# CY8C5568AXI_060 register map
File version: 0.1
CY8C55
Registers are 8-bit, read-write, no defined reset value unless marked. A register's access mark holds for its fields unless they carry their own. Offsets are from the block's base; lines under a group give offsets from that group; [hi:lo] are bit positions; {n}, {i} and the like mark numbered series; 'fields as' and 'values as' point back to an identical list; <NAME> marks a mode.

## Memory map
0x40004614 ADC_Sharp_1 size 0x158D — SAR ADC
0x40004616 ADC_Sharp_2 size 0x158D — SAR ADC
0x40006424 UART_Asser size 0x40 — UART
0x40006425 UART_XBee size 0x47 — UART
0x40006524 PWM_LanceurGauche size 0x72
0x40006526 PWM_LanceurDroit size 0x72
0x40006528 PWM_Queue size 0x72

## ADC_Sharp_1 — SAR ADC
Base 0x40004614
0x00 SAR_TR0 — SAR trim register
{0x12EC+i} SAR_CSR{i} (i=0..6) — SAR status and control register {i}
0x150C SAR_SW0 — SAR Analog Routing Register 0
{0x150C+i} SAR_SW{i} (i=2..4) — SAR Analog Routing Register {i}
0x1512 SAR_SW6 — SAR Analog Routing Register 6
0x1513 SAR_CLK — SAR Clock Selection Register
0x158C SAR_WRK 16-bit — SAR working register

## UART_Asser — UART
Base 0x40006424
0x00 RX_UART_Asser_RX_ADDRESS1 — RX Address1 Register
0x10 RX_UART_Asser_RX_ADDRESS2 — RX Address2 Register
0x1C TX_UART_Asser_TX_DATA — TX Data Register
0x20 RX_UART_Asser_RX_DATA — RX Data Register
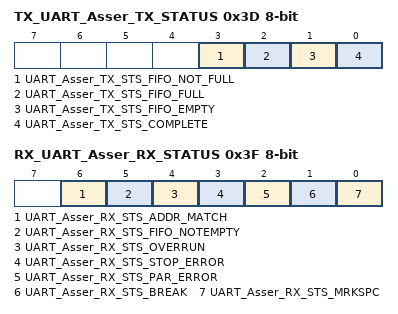
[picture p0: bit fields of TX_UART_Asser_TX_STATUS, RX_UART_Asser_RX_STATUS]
0x3D TX_UART_Asser_TX_STATUS — TX status register
  [3] UART_Asser_TX_STS_FIFO_NOT_FULL ro, [2] UART_Asser_TX_STS_FIFO_FULL ro, [1] UART_Asser_TX_STS_FIFO_EMPTY ro, [0] UART_Asser_TX_STS_COMPLETE ro
0x3F RX_UART_Asser_RX_STATUS — RX status register
  [6] UART_Asser_RX_STS_ADDR_MATCH ro, [5] UART_Asser_RX_STS_FIFO_NOTEMPTY ro, [4] UART_Asser_RX_STS_OVERRUN ro, [3] UART_Asser_RX_STS_STOP_ERROR ro, [2] UART_Asser_RX_STS_PAR_ERROR ro, [1] UART_Asser_RX_STS_BREAK ro, [0] UART_Asser_RX_STS_MRKSPC ro

## UART_XBee — UART
Base 0x40006425
0x00 RX_UART_XBee_RX_ADDRESS1 — RX Address1 Register
0x10 RX_UART_XBee_RX_ADDRESS2 — RX Address2 Register
0x20 RX_UART_XBee_RX_DATA — RX Data Register
0x26 TX_UART_XBee_TX_DATA — TX Data Register
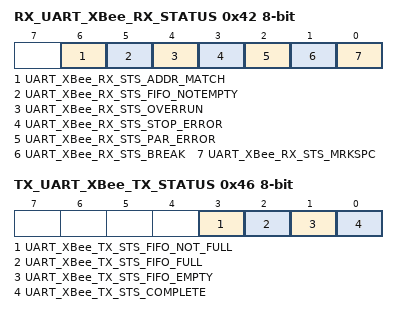
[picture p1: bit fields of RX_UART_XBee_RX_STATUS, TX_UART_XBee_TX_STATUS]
0x42 RX_UART_XBee_RX_STATUS — RX status register
  [6] UART_XBee_RX_STS_ADDR_MATCH ro, [5] UART_XBee_RX_STS_FIFO_NOTEMPTY ro, [4] UART_XBee_RX_STS_OVERRUN ro, [3] UART_XBee_RX_STS_STOP_ERROR ro, [2] UART_XBee_RX_STS_PAR_ERROR ro, [1] UART_XBee_RX_STS_BREAK ro, [0] UART_XBee_RX_STS_MRKSPC ro
0x46 TX_UART_XBee_TX_STATUS — TX status register
  [3] UART_XBee_TX_STS_FIFO_NOT_FULL ro, [2] UART_XBee_TX_STS_FIFO_FULL ro, [1] UART_XBee_TX_STS_FIFO_EMPTY ro, [0] UART_XBee_TX_STS_COMPLETE ro

## PWM_LanceurDroit
Base 0x40006526
0x00 PWM_LanceurDroit_COMPARE_Reg 16-bit — UDB.D0 - Assigned Compare Value
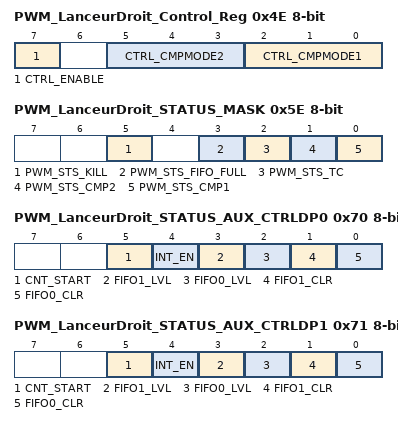
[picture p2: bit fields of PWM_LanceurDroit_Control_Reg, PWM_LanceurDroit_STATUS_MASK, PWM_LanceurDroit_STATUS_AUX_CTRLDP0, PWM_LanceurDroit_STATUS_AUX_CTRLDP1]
0x4E PWM_LanceurDroit_Control_Reg — UDB Control Register - Assigned Control Register Value
  [7] CTRL_ENABLE — Enable the PWM
  [5:3] CTRL_CMPMODE2 — Compare mode 2
  [2:0] CTRL_CMPMODE1 — Compare mode 1
0x5E PWM_LanceurDroit_STATUS_MASK — UDB Status bits Interrupt Mask Enable Register
  [5] PWM_STS_KILL ro — Enables the Interrupt on Kill
  [3] PWM_STS_FIFO_FULL ro — FIFO Full Status Mask
  [2] PWM_STS_TC ro — Enables the Interrupt on Terminal Count
  [1] PWM_STS_CMP2 ro — Enables the Interrupt on Compare 2
  [0] PWM_STS_CMP1 ro — Enables the Interrupt on Compare 1
0x70 PWM_LanceurDroit_STATUS_AUX_CTRLDP0 — UDB Auxilliary Control Register
  [5] CNT_START — FIFO0 clear
    0=E_CNT_START0 (Disable counter); 1=E_CNT_START1 (Enable counter)
  [4] INT_EN
    0=E_INT_EN0 (Interrupt disabled); 1=E_INT_EN1 (Interrupt enabled)
  [3] FIFO1_LVL — FIFO level
    0=E_FIFO_LVL_0 (FIFO LVL: input mode: FIFO not full; output mode: FIFO not empty); 1=E_FIFO_LVL_1 (FIFO LVL: input mode: FIFO at least 1/2 empty; output mode: FIFO at least 1/2 full)
  [2] FIFO0_LVL — FIFO level
    values as FIFO1_LVL
  [1] FIFO1_CLR — FIFO1 clear
    0=E_FIFO_CLR_0 (Normal FIFO operation); 1=E_FIFO_CLR_1 (Clear FIFO state)
  [0] FIFO0_CLR — FIFO0 clear
    values as FIFO1_CLR
0x71 PWM_LanceurDroit_STATUS_AUX_CTRLDP1 — UDB Auxilliary Control Register
  fields as PWM_LanceurDroit_STATUS_AUX_CTRLDP0

## ADC_Sharp_2 — SAR ADC
Base 0x40004616
0x00 SAR_TR0 — SAR trim register
{0x12F2+i} SAR_CSR{i} (i=0..6) — SAR status and control register {i}
0x1512 SAR_SW0 — SAR Analog Routing Register 0
{0x1512+i} SAR_SW{i} (i=2..4) — SAR Analog Routing Register {i}
0x1518 SAR_SW6 — SAR Analog Routing Register 6
0x1519 SAR_CLK — SAR Clock Selection Register
0x158C SAR_WRK 16-bit — SAR working register

## PWM_LanceurGauche
Base 0x40006524
Registers as PWM_LanceurDroit (with PWM_LanceurDroit read as PWM_LanceurGauche), without PWM_LanceurDroit_Control_Reg, PWM_LanceurDroit_STATUS_MASK; these are added or differ:
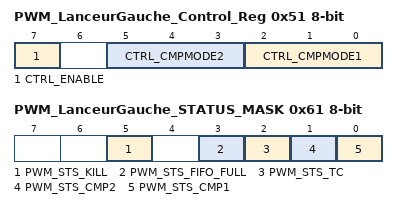
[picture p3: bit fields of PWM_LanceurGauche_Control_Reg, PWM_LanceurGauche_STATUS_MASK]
0x51 PWM_LanceurGauche_Control_Reg — UDB Control Register - Assigned Control Register Value
  [7] CTRL_ENABLE — Enable the PWM
  [5:3] CTRL_CMPMODE2 — Compare mode 2
  [2:0] CTRL_CMPMODE1 — Compare mode 1
0x61 PWM_LanceurGauche_STATUS_MASK — UDB Status bits Interrupt Mask Enable Register
  fields as PWM_LanceurDroit.PWM_LanceurDroit_STATUS_MASK

## PWM_Queue
Base 0x40006528
Registers as PWM_LanceurGauche (with PWM_LanceurGauche read as PWM_Queue).
